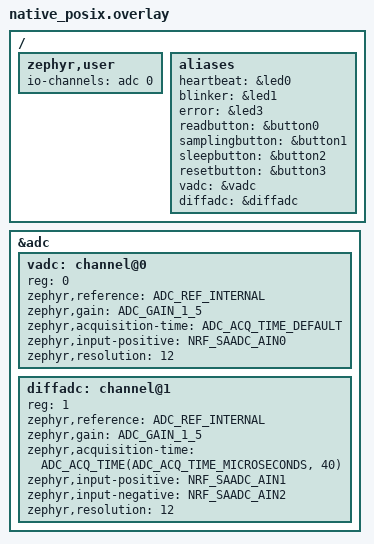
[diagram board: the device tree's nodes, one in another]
/ {
        zephyr,user {
            io-channels = <&adc 0>;
        };
        aliases {
        // add your aliases here; examples:
        heartbeat = &led0;  // this corresponds to LED1 on the board
        blinker = &led1;
        // buzzer = &led2;
        error = &led3;
        readbutton = &button0;  // this corresponds to SW1 on the board
        samplingbutton = &button1;
        sleepbutton = &button2;
        resetbutton = &button3;
        vadc = &vadc;
        diffadc = &diffadc;
        };
};

&adc {
    #address-cells = <1>;
    #size-cells = <0>;

    vadc: channel@0 {
        reg = <0>;  // channel number
        zephyr,reference = "ADC_REF_INTERNAL";  // voltage ref for SA (0.6 V)
        zephyr,gain = "ADC_GAIN_1_5"; // gain factor to scale ref voltage (1/gain)
        zephyr,acquisition-time = <ADC_ACQ_TIME_DEFAULT>;
        zephyr,input-positive = <NRF_SAADC_AIN0>; // P0.02
        zephyr,resolution = <12>;  // bit depth
    };
    diffadc: channel@1 {
        reg = <1>;  // channel number
        zephyr,reference = "ADC_REF_INTERNAL";
        zephyr,gain = "ADC_GAIN_1_5";
        zephyr,acquisition-time = <ADC_ACQ_TIME(ADC_ACQ_TIME_MICROSECONDS, 40)>;
        zephyr,input-positive = <NRF_SAADC_AIN1>; // P0.03
        zephyr,input-negative = <NRF_SAADC_AIN2>; // P0.04
        zephyr,resolution = <12>;
    };
    status = "okay"; // enable the ADC
};
